VERSION ""

NS_ :

BS_:

BU_: XXX

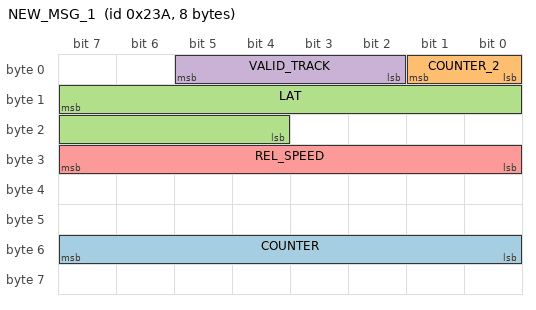
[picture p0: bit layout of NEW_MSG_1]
BO_ 570 NEW_MSG_1: 8 XXX
 SG_ COUNTER : 48|8@1+ (1,0) [0|255] "" XXX
 SG_ COUNTER_2 : 1|2@0+ (1,0) [0|255] "" XXX
 SG_ LAT : 15|12@0- (1,0) [0|255] "" XXX
 SG_ VALID_TRACK : 5|4@0+ (1,0) [0|1] "" XXX
 SG_ REL_SPEED : 24|8@1- (-.6,38.4) [0|255] "" XXX

BO_ 571 NEW_MSG_2: 8 XXX
